# STM32L152xBA register map
File version: 1.0
Registers are 32-bit, read-write, reset 0x0 unless marked. A register's access mark holds for its fields unless they carry their own. Offsets are from the block's base; [hi:lo] are bit positions; {n}, {i} and the like mark numbered series.

## RI — Routing Interface
Base 0x40007C04
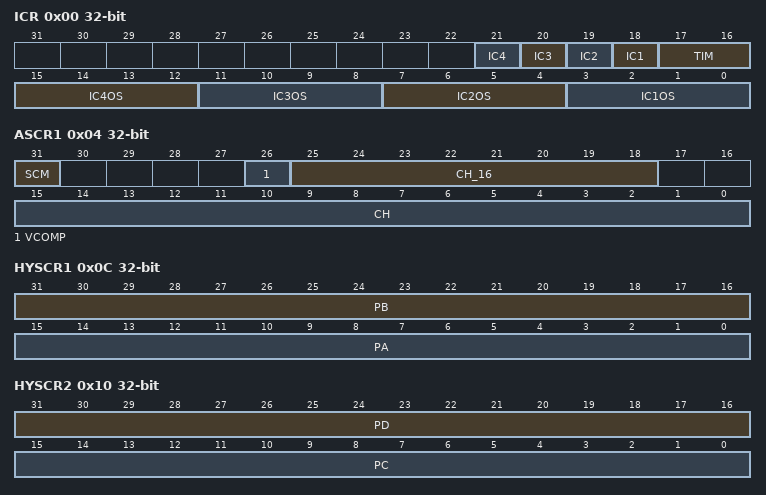
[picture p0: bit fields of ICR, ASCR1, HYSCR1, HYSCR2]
0x00 ICR — RI input capture register
  [n+17] IC{n} (n=1..4) — Input capture {n}
  [17:16] TIM — TIM[3:0] bits (Timers select bits)
  [4n-1:4n-4] IC{n}OS (n=1..4) — IC{n}OS[3:0] bits (Input Capture {n} select bits)
0x04 ASCR1 — RI analog switches control register
  [31] SCM — I/O Switch control mode
  [26] VCOMP — ADC analog switch selection for internal node to COMP1
  [25:18] CH_16 — AS_CH[25:18] & AS_CH[15:0] bits ( Analog switches selection bits)
  [15:0] CH — AS_CH[25:18] & AS_CH[15:0] bits ( Analog switches selection bits)
0x08 ASCR2 — RI analog switch control register 2
  [5:4] GR6 — GR6 selection bits
0x0C HYSCR1 — RI hysteresis control register
  [31:16] PB — PB[15:0] Port B Hysteresis selection
  [15:0] PA — PA[15:0] Port A Hysteresis selection
0x10 HYSCR2 — RI Hysteresis control register
  [31:16] PD — PD[15:0] Port D Hysteresis selection
  [15:0] PC — PC[15:0] Port C Hysteresis selection
0x14 HYSCR3 — RI Hysteresis control register
  [15:0] PE — PE[15:0] Port E Hysteresis selection

## SYSCFG — SysTem Configuration
Base 0x40010000
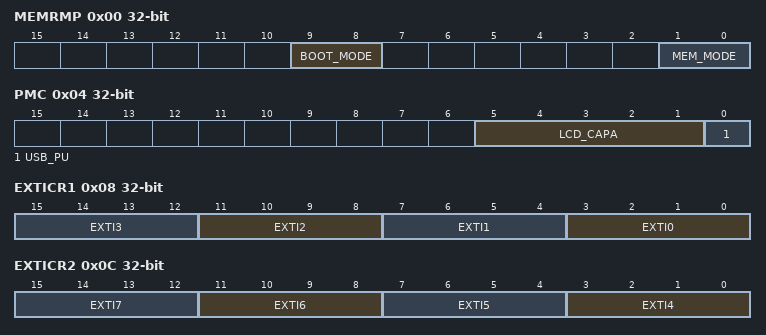
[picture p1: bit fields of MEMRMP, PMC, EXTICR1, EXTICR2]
0x00 MEMRMP — SYSCFG memory remap register
  [9:8] BOOT_MODE — Boot mode Config
    0=FLASH; 1=SYSTEMFLASH; 3=SRAM
  [1:0] MEM_MODE — SYSCFG_Memory Remap Config
    0=FLASH; 1=SYSTEMFLASH; 3=SRAM
0x04 PMC — SYSCFG peripheral mode configuration register
  [5:1] LCD_CAPA — LCD_CAPA decoupling capacitance connection
  [0] USB_PU — SYSCFG PMC
0x08 EXTICR1 — SYSCFG external interrupt configuration registers
  [4n+3:4n] EXTI{n} (n=0..3) — EXTI {n} configuration
0x0C EXTICR2 — SYSCFG external interrupt configuration registers
  [4n-13:4n-16] EXTI{n} (n=4..7) — EXTI {n} configuration
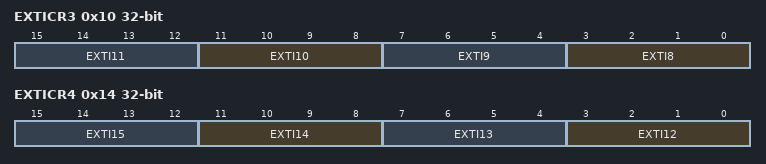
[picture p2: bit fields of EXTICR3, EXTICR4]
0x10 EXTICR3 — SYSCFG external interrupt configuration registers
  [4n-29:4n-32] EXTI{n} (n=8..11) — EXTI {n} configuration
0x14 EXTICR4 — SYSCFG external interrupt configuration registers
  [4n-45:4n-48] EXTI{n} (n=12..15) — EXTI {n} configuration

## EXTI — External Interrupt/Event Controller
Base 0x40010400
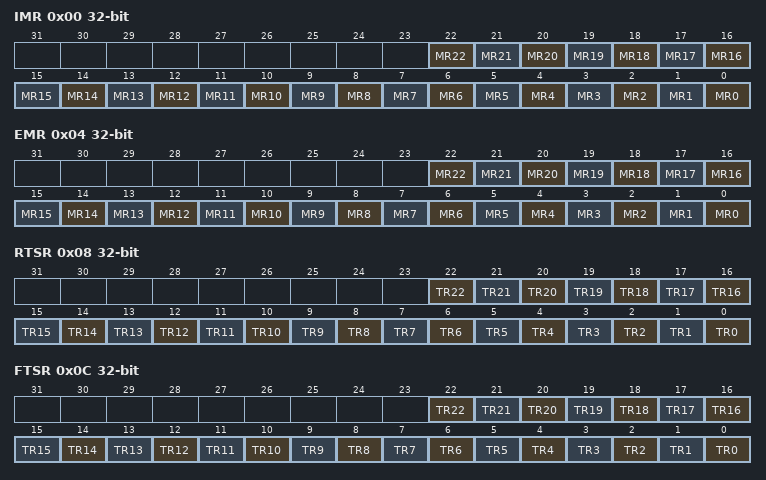
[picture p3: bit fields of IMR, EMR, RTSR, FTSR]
0x00 IMR — EXTI Interrupt mask register
  [n] MR{n} (n=0..22) — Interrupt Mask on line {n}
0x04 EMR — EXTI Event mask register
  [n] MR{n} (n=0..22) — Event Mask on line {n}
0x08 RTSR — EXTI Rising trigger selection register
  [n] TR{n} (n=0..22) — Rising trigger event configuration bit of line {n}
0x0C FTSR — EXTI Falling trigger selection register
  [n] TR{n} (n=0..22) — Falling trigger event configuration bit of line {n}
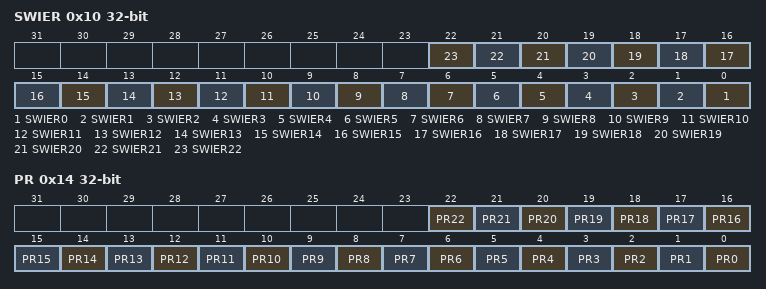
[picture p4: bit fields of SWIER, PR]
0x10 SWIER — EXTI Software interrupt event register
  [n] SWIER{n} (n=0..22) — Software Interrupt on line {n}
0x14 PR — EXTI Pending register
  [n] PR{n} (n=0..22) — Pending bit for line {n}

## GPIOA — General Purpose IO
Base 0x40020000
Same registers: GPIOB 0x40020400, GPIOC 0x40020800, GPIOD 0x40020C00, GPIOE 0x40021000, GPIOH 0x40021400
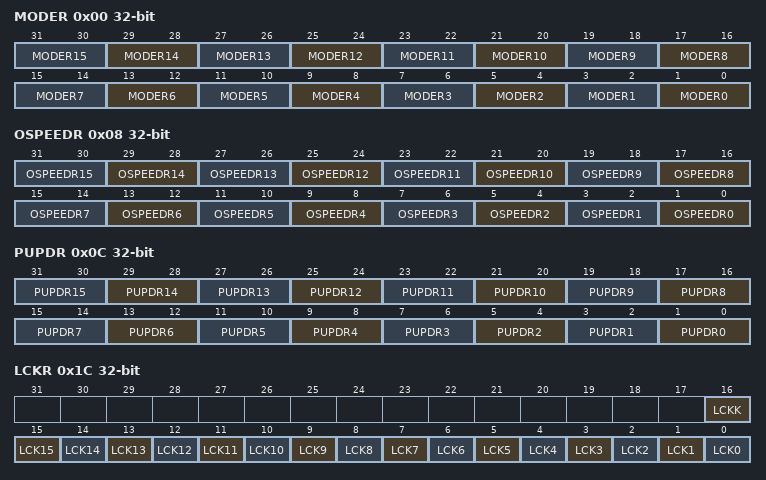
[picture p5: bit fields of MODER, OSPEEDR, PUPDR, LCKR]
0x00 MODER — GPIO port mode register
  [2n+1:2n] MODER{n} (n=0..15)
0x04 OTYPER — GPIO port output type register
0x08 OSPEEDR — GPIO port output speed register
  [2n+1:2n] OSPEEDR{n} (n=0..15)
0x0C PUPDR — GPIO port pull-up/pull-down register
  [2n+1:2n] PUPDR{n} (n=0..15)
0x10 IDR — GPIO port input data register
0x14 ODR — GPIO port output data register
0x18 BSRR — GPIO port bit set/reset registerBSRR
0x1C LCKR — GPIO port configuration lock register
  [16] LCKK, [n] LCK{n} (n=0..15)
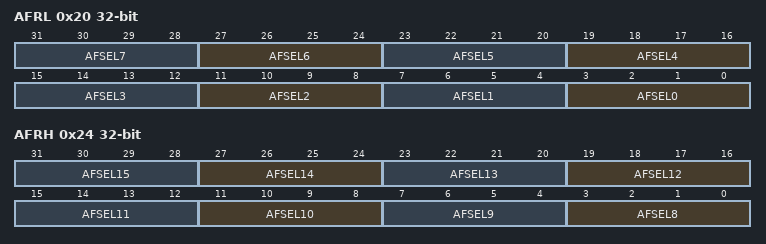
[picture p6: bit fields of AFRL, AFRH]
0x20 AFRL — GPIO alternate function register
  [4n+3:4n] AFSEL{n} (n=0..7)
0x24 AFRH — GPIO alternate function register
  [4n-29:4n-32] AFSEL{n} (n=8..15)

## CRC — CRC calculation unit
Base 0x40023000
0x00 DR — CRC Data register
  [31:0] DR — Data register bits
0x04 IDR 8-bit — CRC Independent data register
  [7:0] IDR — General-purpose 8-bit data register bits
0x08 CR — CRC Control register
  [0] RESET — RESET bit
